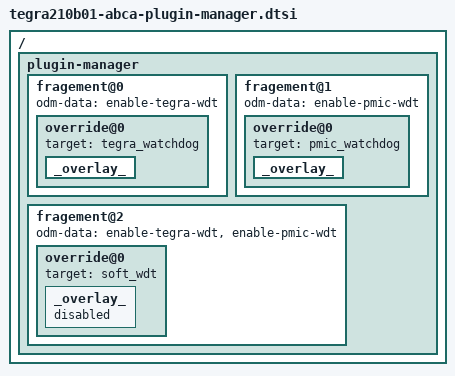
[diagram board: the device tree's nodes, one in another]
/*
 * Copyright (c) 2017, NVIDIA CORPORATION.  All rights reserved.
 *
 * This program is free software; you can redistribute it and/or modify
 * it under the terms of the GNU General Public License as published by
 * the Free Software Foundation; version 2 of the License.
 *
 * This program is distributed in the hope that it will be useful, but WITHOUT
 * ANY WARRANTY; without even the implied warranty of MERCHANTABILITY or
 * FITNESS FOR A PARTICULAR PURPOSE.  See the GNU General Public License for
 * more details.
 *
 */

/ {
	plugin-manager {
		fragement@0 {
			odm-data = "enable-tegra-wdt";
			override@0 {
				target = <&tegra_watchdog>;
				_overlay_ {
					status = "okay";
				};
			};
		};

		fragement@1 {
			odm-data = "enable-pmic-wdt";
			override@0 {
				target = <&pmic_watchdog>;
				_overlay_ {
					status = "okay";
				};
			};
		};

		fragement@2 {
			odm-data = "enable-tegra-wdt",
			"enable-pmic-wdt";
			override@0 {
				target = <&soft_wdt>;
				_overlay_ {
					status = "disabled";
				};
			};
		};
	};
};
